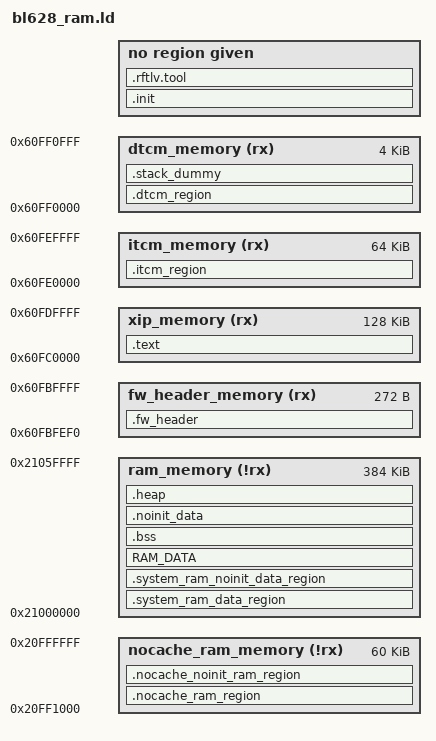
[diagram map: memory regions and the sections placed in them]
/****************************************************************************************
* @file flash.ld
*
* @brief This file is the link script file (gnuarm or armgcc).
*
* Copyright (C) BouffaloLab 2021
*
****************************************************************************************
*/

/* configure the CPU type */
OUTPUT_ARCH( "riscv" )

/* configure the entry point */
ENTRY(__start)

StackSize    = 0x1000; /*  1KB */
HeapMinSize  = 0x1000; /*  4KB */

MEMORY
{
    fw_header_memory  (rx)  : ORIGIN = 0x60FC0000 - (256+16), LENGTH = 256+16
    xip_memory  (rx)  : ORIGIN = 0x60FC0000, LENGTH = 128K
    itcm_memory (rx)  : ORIGIN = 0x60FE0000, LENGTH = 64K
    dtcm_memory (rx)  : ORIGIN = 0x60FF0000, LENGTH = 4K
    nocache_ram_memory (!rx) : ORIGIN = 0x20FF1000, LENGTH = 60K
    ram_memory  (!rx) : ORIGIN = 0x21000000 , LENGTH = 640K-256K
}

SECTIONS
{
    BOOT2_PT_ADDR = 0x63027c00;

    .fw_header :
    {
        KEEP(*(.fw_header))
        LONG(ORIGIN(code_memory))
        LONG(0x48474553)
    } > fw_header_memory

    .init :
    {
        KEEP (*(SORT_NONE(.init)))
        KEEP (*(SORT_NONE(.vector)))

    } > code_memory

    .rftlv.tool :
    {
        . = ORIGIN(code_memory) + __RFTLV_SIZE_OFFSET;
        PROVIDE( _ld_symbol_rftlv_address = . );
        LONG(__RFTLV_HEAD1_H);
        LONG(__RFTLV_HEAD1_L);
        . = ORIGIN(code_memory) + __RFTLV_SIZE_OFFSET + __RFTLV_SIZE_HOLE;
    } > code_memory

    .text :
    {
        . = ALIGN(4);
        __text_code_start__ = .;

        *(.text)
        *(.text.*)

        /* section information for shell */
        . = ALIGN(4);
        __fsymtab_start = .;
        KEEP(*(FSymTab))
        __fsymtab_end = .;

        . = ALIGN(4);
        __vsymtab_start = .;
        KEEP(*(VSymTab))
        __vsymtab_end = .;

        /* section information for usb usbh_class_info */
        . = ALIGN(4);
        __usbh_class_info_start__ = .;
        KEEP(*(.usbh_class_info))
        . = ALIGN(4);
        __usbh_class_info_end__ = .;

        *(.srodata)
        *(.srodata.*)

        . = ALIGN(4);
        __text_code_end__ = .;
    } > xip_memory

    . = ALIGN(4);
    __itcm_load_addr = .;

    .itcm_region : AT (__itcm_load_addr)
    {
        . = ALIGN(4);
        __tcm_code_start__ = .;

        *(.tcm_code.*)
        *(.tcm_const.*)
        *(.sclock_rlt_code.*)
        *(.sclock_rlt_const.*)

        . = ALIGN(4);
        __tcm_code_end__ = .;
    } > itcm_memory

    __dtcm_load_addr = __itcm_load_addr + SIZEOF(.itcm_region);

    .dtcm_region : AT (__dtcm_load_addr)
    {
        . = ALIGN(4);
        __tcm_data_start__ = .;

        *(.tcm_data)
        /* *finger_print.o(.data*) */

        . = ALIGN(4);
        __tcm_data_end__ = .;
    } > dtcm_memory

    /*************************************************************************/
    /* .stack_dummy section doesn't contains any symbols. It is only
     * used for linker to calculate size of stack sections, and assign
     * values to stack symbols later */
    .stack_dummy (NOLOAD):
    {
        . = ALIGN(0x4);
        . = . + StackSize;
        . = ALIGN(0x4);
    } > dtcm_memory

    /* Set stack top to end of RAM, and stack limit move down by
     * size of stack_dummy section */
    __StackTop = ORIGIN(dtcm_memory) + LENGTH(dtcm_memory);
    PROVIDE( __freertos_irq_stack_top = __StackTop);
    __StackLimit = __StackTop - SIZEOF(.stack_dummy);

    /* Check if data + heap + stack exceeds RAM limit */
    ASSERT(__StackLimit >= __tcm_data_end__, "region RAM overflowed with stack")
    /*************************************************************************/
    __nocache_ram_load_addr = __dtcm_load_addr + SIZEOF(.dtcm_region);

    .nocache_ram_region  : AT (__nocache_ram_load_addr)
    {
        . = ALIGN(4);
        __nocache_ram_data_start__ = .;

        *(.nocache_ram)

        . = ALIGN(4);
        __nocache_ram_data_end__ = .;
    } > nocache_ram_memory

    __system_ram_load_addr = __nocache_ram_load_addr + SIZEOF(.nocache_ram_region);

    .system_ram_data_region : AT (__system_ram_load_addr)
    {
        . = ALIGN(4);
        __system_ram_data_start__ = .;

        *(.system_ram)

        . = ALIGN(4);
        __system_ram_data_end__ = .;
    } > ram_memory

    .system_ram_noinit_data_region (NOLOAD) :
    {
        . = ALIGN(4);
        *(.system_ram_noinit)

        . = ALIGN(4);
    } > ram_memory

    __ram_load_addr = __system_ram_load_addr + SIZEOF(.system_ram_data_region);

    /* Data section */
    RAM_DATA : AT (__ram_load_addr)
    {
        . = ALIGN(4);
        __ram_data_start__ = .;

        PROVIDE( __global_pointer$ = . + 0x800 );

        *(.data)
        *(.data.*)
        *(.sdata)
        *(.sdata.*)
        *(.sdata2)
        *(.sdata2.*)

        . = ALIGN(4);
        __bflog_tags_start__ = .;
        *(.bflog_tags_array)
        . = ALIGN(4);
        __bflog_tags_end__ = .;
        __ram_data_end__ = .;
    } > ram_memory

    __etext_final = (__ram_load_addr + SIZEOF (RAM_DATA));
    ASSERT(__etext_final <= ORIGIN(xip_memory) + LENGTH(xip_memory), "code memory overflow")

    .bss (NOLOAD) :
    {
        . = ALIGN(4);
        __bss_start__ = .;

        *(.bss*)
        *(.sbss*)
        *(COMMON)

        . = ALIGN(4);
        __bss_end__ = .;
    } > ram_memory

    .noinit_data (NOLOAD) :
    {
        . = ALIGN(4);
        __noinit_data_start__ = .;

        *(.noinit_data*)

        . = ALIGN(4);
        __noinit_data_end__ = .;
    } > ram_memory

    .nocache_noinit_ram_region (NOLOAD) :
    {
        . = ALIGN(4);
        __nocache_noinit_ram_data_start__ = .;

        *(.nocache_noinit_ram)
        *(.noncacheable)

        . = ALIGN(4);
        __nocache_noinit_ram_data_end__ = .;
    } > nocache_ram_memory

    .heap (NOLOAD):
    {
        . = ALIGN(4);
        __HeapBase = .;

        /*__end__ = .;*/
        /*end = __end__;*/
        KEEP(*(.heap*))

        . = ALIGN(4);
        __HeapLimit = .;
    } > ram_memory

    __HeapLimit = ORIGIN(ram_memory) + LENGTH(ram_memory);
    ASSERT(__HeapLimit - __HeapBase >= HeapMinSize, "heap region overflow")

}

